# MINI51XAE_v1 register map
File version: 1.0
Registers are 32-bit, read-write, reset 0x0 unless marked. A register's access mark holds for its fields unless they carry their own. Offsets are from the block's base; [hi:lo] are bit positions; {n}, {i} and the like mark numbered series; 'fields as' and 'values as' point back to an identical list.

## TMR — TMR Register Map
Base 0x40010000
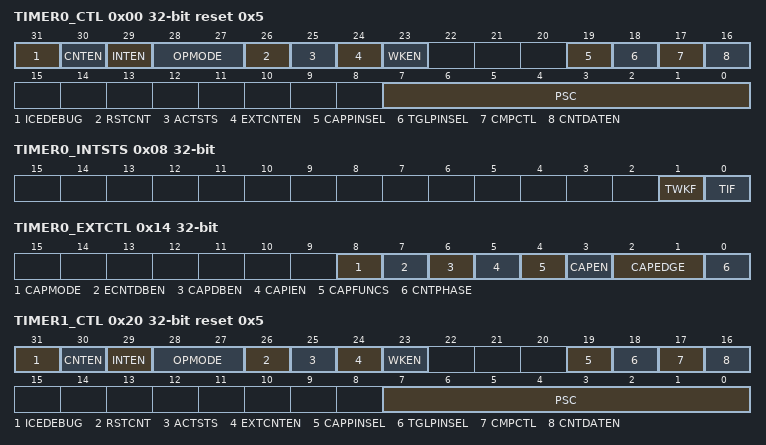
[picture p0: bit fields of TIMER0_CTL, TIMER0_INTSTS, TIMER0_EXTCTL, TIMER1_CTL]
0x00 TIMER0_CTL reset 0x5 — Timer0 Control and Status Register
  [31] ICEDEBUG — ICE Debug Mode Acknowledge Disable (Write Protect). Timer counter will keep going no matter CPU is held by ICE or not.
    0=ICE debug mode acknowledgement effects TIMER counting; 1=ICE debug mode acknowledgement Disabled
  [30] CNTEN — Timer Enable Control
    0=Stops/Suspends counting; 1=Starts counting
  [29] INTEN — Interrupt Enable Control. If this bit is enabled, when the timer interrupt flag (TIF) is set to 1, the timer interrupt signal is generated and inform to CPU.
    0=Timer Interrupt function Disabled; 1=Timer Interrupt function Enabled
  [28:27] OPMODE — Timer Operating Mode
    0=The timer is operating in the One-shot OPMODE. The associated interrupt signal is generated once (if INTEN is enabled) and CNTEN is automatically cleared by hardware; 1=The timer is operating in Periodic OPMODE. The associated interrupt signal is generated periodically (if INTEN is enabled); 2=The timer is operating in Toggle OPMODE. The interrupt signal is generated periodically (if INTEN is enabled). The associated signal (tout) is changing back and forth with 50% duty cycle; 3=The timer is operating in Continuous Counting mode. The associated interrupt signal is generated when TIMERx_CNT = TIMERx_CMP (if INTEN is enabled). However, the 24-bit up-timer counts continuously. Please refer to 6.12.5.2 for detailed description about Continuous Counting mode operation
  [26] RSTCNT — Timer Reset
    0=No effect; 1=Reset 8-bit PSC counter, 24-bit up counter value and CNTEN bit if ACTSTS is 1
  [25] ACTSTS ro — Timer Active Status (Read Only). This bit indicates the 24-bit up counter status.
    0=24-bit up counter is not active; 1=24-bit up counter is active
  [24] EXTCNTEN — Counter Mode Enable Control. This bit is for external counting pin function enabled. When timer is used as an event counter, this bit should be set to 1 and select HCLK as timer clock source. Please refer to section 6.12.5.3 for detail description.
    0=External event counter mode Disabled; 1=External event counter mode Enabled
  [23] WKEN — Wake-Up Enable. When WKEN is set and the TIF or CAPIF is set, the timer controller will generator a wake-up trigger event to CPU.
    0=Wake-up trigger event Disabled; 1=Wake-up trigger event Enabled
  [19] CAPPINSEL — Capture Pin Source Selection
    0=Capture Function source is from TxEX pin; 1=Capture Function source is from ACMPx output signal
  [18] TGLPINSEL — Toggle Out Pin Selection. When Timer is set to toggle mode,
    0=Time0/1 toggle output pin is T0/T1 pin; 1=Time0/1 toggle output pin is T0EX/T1EX pin
  [17] CMPCTL — TIMERx_CMP Mode Control
    0=In One-shot or Periodic mode, when write new CMPDAT, timer counter will reset; 1=In One-shot or Periodic mode, when write new CMPDAT if new CMPDAT CNT (TIMERx_CNT[23:0])(current counter) , timer counter keep counting and will not reset. If new CMPDAT = CNT(current counter) , timer counter will reset
  [16] CNTDATEN — Data Load Enable Control. When CNTDATEN is set, CNT (TIMERx_CNT[23:0]) (Timer Data Register) will be updated continuously with the 24-bit up-timer value as the timer is counting.
    0=Timer Data Register update Disabled; 1=Timer Data Register update Enabled while Timer counter is active
  [7:0] PSC — Prescale Counter
0x04 TIMER0_CMP — Timer0 Compare Register
  [23:0] CMPDAT — Timer Compared Value. CMPDAT is a 24-bit compared value register. When the internal 24-bit up counter value is equal to CMPDAT value, the TIF flag will set to 1. Note1: Never write 0x0 or 0x1 in CMPDAT field, or the core will run into unknown state. Note2: When Timer is operating at Continuous Counting mode, the 24-bit up counter will keep counting continuously even if software writes a new value into CMPDAT field. But if Timer is operating at other modes except Periodic mode on M05xxDN/DE, the 24-bit up counter will restart counting and using newest CMPDAT value to be the timer compared value if software writes a new value into CMPDAT field.
0x08 TIMER0_INTSTS — Timer0 Interrupt Status Register
  [1] TWKF — Timer Wake-Up Flag. This bit indicates the interrupt wake-up flag status of Time. Note: This bit is cleared by writing 1 to it.
    0=Timer does not cause chip wake-up; 1=Chip wake-up from Idle or Power-down mode if Timer time-out interrupt signal generated
  [0] TIF — Timer Interrupt Flag. This bit indicates the interrupt flag status of Timer while CNT (TIMERx_CNT[23:0]) value reaches to CMPDAT value. Note: This bit is cleared by writing 1 to it.
    0=No effect; 1=CNT value matches the CMPDAT value
0x0C TIMER0_CNT ro — Timer0 Data Register
  [23:0] CNT — Timer Data Register. If CNTDATEN is set to 1, CNT register value will be updated continuously to monitor 24-bit up counter value.
0x10 TIMER0_CAP ro — Timer0 Capture Data Register
  [23:0] CAPDAT — Timer Capture Data Register. When CAPIF flag is set to 1, the current CNT (TIMERx_CNT[23:0]) value will be auto-loaded into this TCAP filed immediately.
0x14 TIMER0_EXTCTL — Timer0 External Control Register
  [8] CAPMODE — Capture Mode Selection
    0=Timer counter reset function or free-counting mode of timer capture function; 1=Trigger-counting mode of timer capture function
  [7] ECNTDBEN — Timer External Counter Input Pin De-Bounce Enable Control
    0=Tx (x = 0~1) pin de-bounce Disabled; 1=Tx (x = 0~1) pin de-bounce Enabled
  [6] CAPDBEN — Timer External Capture Input Pin De-Bounce Enable Control
    0=TxEX (x = 0~1) pin de-bounce Disabled; 1=TxEX (x = 0~1) pin de-bounce Enabled
  [5] CAPIEN — Timer External Capture Interrupt Enable Control. If CAPIEN enabled, Timer will raise an external capture interrupt signal and inform to CPU while CAPIF flag is set to 1.
    0=TxEX (x = 0~1) pin detection Interrupt Disabled; 1=TxEX (x = 0~1) pin detection Interrupt Enabled
  [4] CAPFUNCS — Timer External Reset Counter / Timer External Capture Mode Selection
    0=Transition on TxEX (x = 0~1) pin is using to save the CNT (TIMERx_CNT[23:0]) value into TCAP value if CAPIF flag is set to 1; 1=Transition on TxEX (x = 0~1) pin is using to reset the 24-bit up counter
  [3] CAPEN — Timer External Pin Function Enable
    0=CAPFUNCS function of TxEX (x = 0~1) pin will be ignored; 1=CAPFUNCS function of TxEX (x = 0~1) pin is active
  [2:1] CAPEDGE — Timer External Pin Edge Detection
    0=A 1 to 0 transition on TxEX (x = 0~1) will be detected; 1=A 0 to 1 transition on TxEX (x = 0~1) will be detected; 2=Either 1 to 0 or 0 to 1 transition on TxEX (x = 0~1) will be detected
  [0] CNTPHASE — Timer External Count Pin Phase Detect Selection
    0=A falling edge of Tx (x = 0~1) pin will be counted; 1=A rising edge of Tx (x = 0~1) pin will be counted
0x18 TIMER0_EINTSTS — Timer0 External Interrupt Status Register
  [0] CAPIF — Timer External Interrupt Flag. This bit indicates the external capture interrupt flag status. Note: This bit is cleared by writing 1 to it
    0=TxEX (x = 0~1) pin interrupt did not occur; 1=TxEX (x = 0~1) pin interrupt occurred
0x20 TIMER1_CTL reset 0x5 — Timer1 Control and Status Register
  fields as TIMER0_CTL
0x24 TIMER1_CMP — Timer1 Compare Register
  fields as TIMER0_CMP
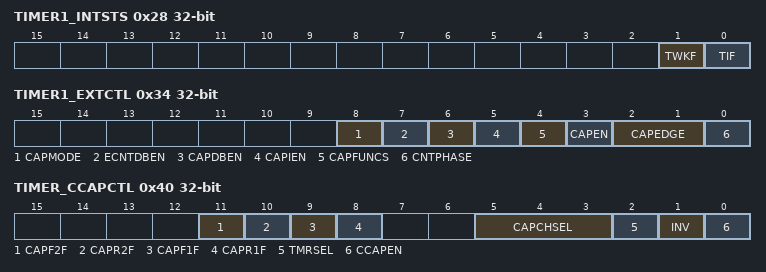
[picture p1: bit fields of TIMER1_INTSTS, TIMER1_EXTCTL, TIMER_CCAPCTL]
0x28 TIMER1_INTSTS — Timer1 Interrupt Status Register
  fields as TIMER0_INTSTS
0x2C TIMER1_CNT ro — Timer1 Data Register
  fields as TIMER0_CNT
0x30 TIMER1_CAP ro — Timer1 Capture Data Register
  fields as TIMER0_CAP
0x34 TIMER1_EXTCTL — Timer1 External Control Register
  fields as TIMER0_EXTCTL
0x38 TIMER1_EINTSTS — Timer1 External Interrupt Status Register
  fields as TIMER0_EINTSTS
0x40 TIMER_CCAPCTL — Timer Continuous Capture Control Register
  [11] CAPF2F — Capture Falling Edge 2 Flag. Second falling edge already captured, this bit will be set to 1. Note: This bit is cleared by H/W automatically when write CCAPEN to 1 or writing 1 to it
    0=None; 1=TIMER0_CAP or TIMER1_CAP data is ready for read
  [10] CAPR2F — Capture Rising Edge 2 Flag. Second rising edge already captured, this bit will be set to 1. Note: This bit is cleared by H/W automatically when write CCAPEN to 1 or writing 1 to it
    0=None; 1=TIMER_CCAP2 data is ready for read
  [9] CAPF1F — Capture Falling Edge 1 Flag. First falling edge already captured, this bit will be set to 1. Note: This bit is cleared by H/W automatically when write CCAPEN to 1 or writing 1 to it
    0=None; 1=TIMER_CCAP1 data is ready for read
  [8] CAPR1F — Capture Rising Edge 1 Flag. First rising edge already captured, this bit will be set to 1. Note: This bit is cleared by H/W automatically when write CCAPEN to 1 or writing 1 to it
    0=None; 1=TIMER_CCAP0 data is ready for read
  [5:3] CAPCHSEL — Capture Channel Selection. Select the input channel to be captured.
    0=P0.0; 1=P0.4; 2=P0.5; 3=P0.6; 4=P0.7; 5=P5.2; 6=P3.0; 7=P3.1
  [2] TMRSEL — Capture Timer Selection. Select the timer to capture the input signal.
    0=Timer 0; 1=Timer 1
  [1] INV — Input Signal Inverse. Invert the input signal which be captured.
    0=None; 1=Inverse
  [0] CCAPEN — Continuous Capture Enable. This bit enables the advanced capture function. Note: This bit is cleared by H/W automatically when capture operation finish or writing 0 to it
    0=Enable; 1=Disable
{0x44+4i} TIMER_CCAP{i} ro (i=0..2) — Timer Continuous Capture Data Register {i}
  [23:0] CAPDAT — Timer Continuous Capture Data Register X. TIMER_CCAP0 store the timer count value of first rising edge. TIMER_CCAP1 store the timer count value of first falling edge. TIMER_CCAP2 store the timer count value of second rising edge.
